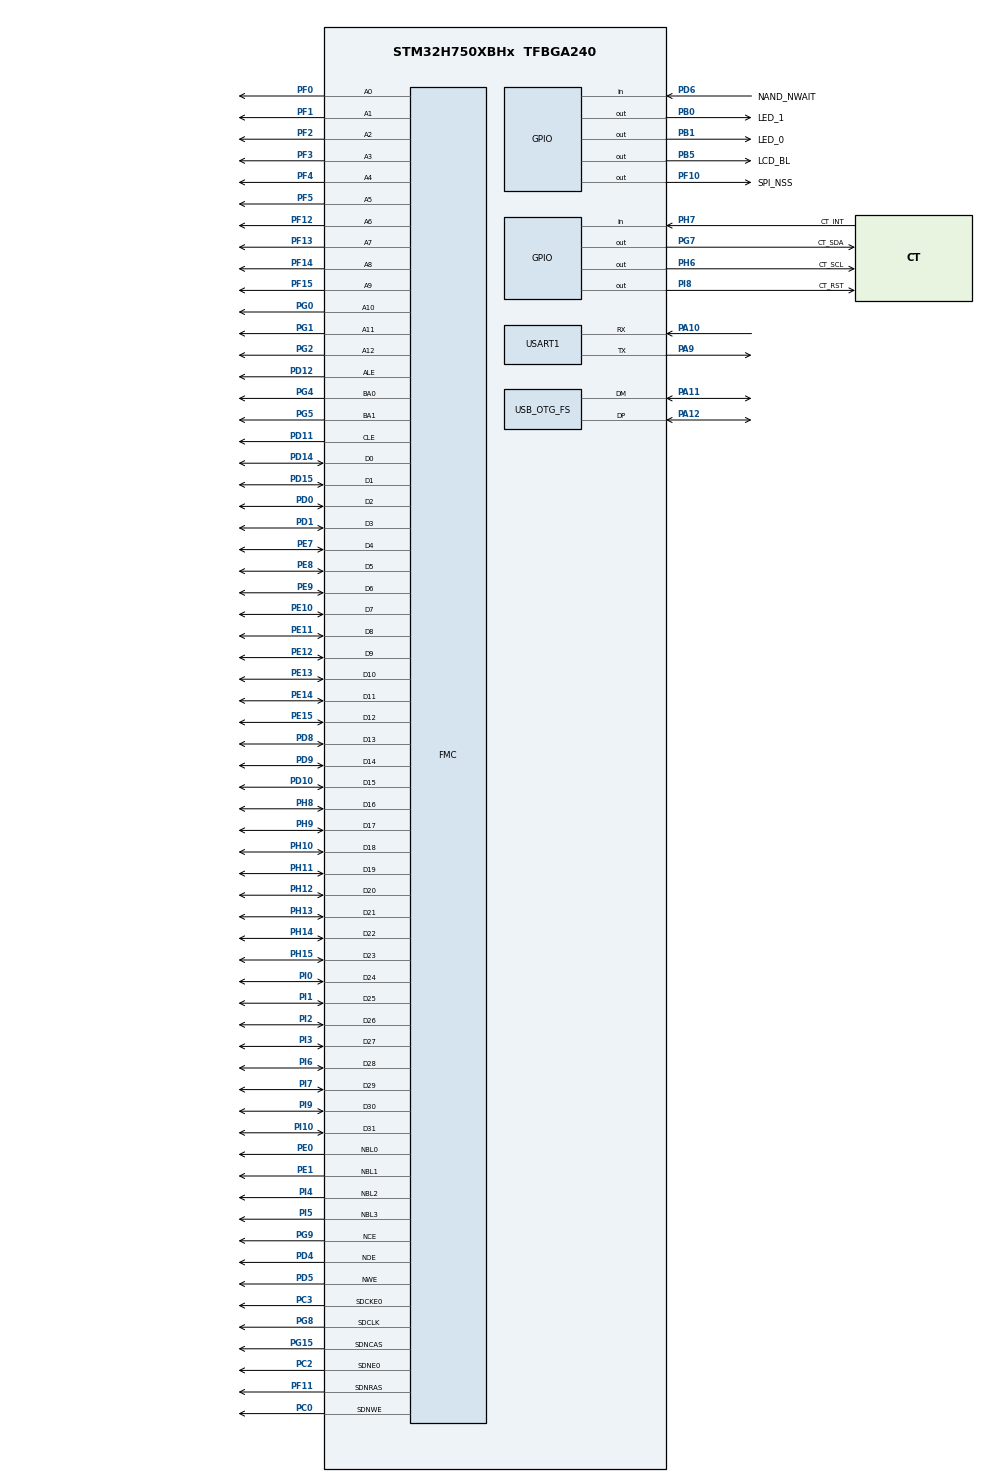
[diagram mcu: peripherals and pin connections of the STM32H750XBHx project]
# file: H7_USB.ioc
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CORTEX_M7.CPU_DCache=Enabled
CORTEX_M7.CPU_ICache=Enabled
CORTEX_M7.MPU_Control=__NULL
FMC.AttributeSpaceHiZSetupTime1=10
FMC.AttributeSpaceHoldSetupTime1=10
FMC.AttributeSpaceSetupTime1=10
FMC.AttributeSpaceWaitSetupTime1=10
FMC.CASLatency1=FMC_SDRAM_CAS_LATENCY_2
FMC.ColumnBitsNumber1=FMC_SDRAM_COLUMN_BITS_NUM_9
FMC.CommonSpaceHiZSetupTime1=10
FMC.CommonSpaceHoldSetupTime1=10
FMC.CommonSpaceSetupTime1=10
FMC.CommonSpaceWaitSetupTime1=10
FMC.ECCPageSize1=FMC_NAND_ECC_PAGE_SIZE_512BYTE
FMC.ExitSelfRefreshDelay1=8
FMC.LoadToActiveDelay1=2
FMC.NandBlockNbr1=2048
FMC.NandBlockSize1=64
FMC.NandPageSize1=2048
FMC.NandPlaneNbr1=2
FMC.NandPlaneSize1=4096
FMC.NandSpareAreaSize1=64
FMC.RCDDelay1=2
FMC.RPDelay1=2
FMC.RPDelay2=2
FMC.ReadBurst1=FMC_SDRAM_RBURST_ENABLE
FMC.ReadBurst2=FMC_SDRAM_RBURST_ENABLE
FMC.RowCycleDelay1=6
FMC.RowCycleDelay2=6
FMC.SDClockPeriod1=FMC_SDRAM_CLOCK_PERIOD_2
FMC.SDClockPeriod2=FMC_SDRAM_CLOCK_PERIOD_2
FMC.SelfRefreshTime1=6
FMC.TARSetupTime1=10
FMC.TCLRSetupTime1=10
FMC.WriteRecoveryTime1=4
Mcu.Family=STM32H7
Mcu.Name=STM32H750XBHx
Mcu.Package=TFBGA240
NVIC.FMC_IRQn=true\:0\:0\:false\:false\:true\:true\:true\:true
NVIC.OTG_FS_EP1_IN_IRQn=true\:0\:0\:false\:false\:true\:true\:true\:true
NVIC.OTG_FS_EP1_OUT_IRQn=true\:0\:0\:false\:false\:true\:true\:true\:true
NVIC.OTG_FS_IRQn=true\:1\:0\:true\:false\:true\:false\:true\:true
NVIC.PriorityGroup=NVIC_PRIORITYGROUP_4
PA10.Mode=Asynchronous
PA10.Signal=USART1_RX
PA11.GPIO_Speed=GPIO_SPEED_FREQ_MEDIUM
PA11.Mode=Device_Only
PA11.Signal=USB_OTG_FS_DM
PA12.GPIO_Speed=GPIO_SPEED_FREQ_MEDIUM
PA12.Mode=Device_Only
PA12.Signal=USB_OTG_FS_DP
PA13\ (JTMS/SWDIO).Mode=Serial_Wire
PA13\ (JTMS/SWDIO).Signal=DEBUG_JTMS-SWDIO
PA14\ (JTCK/SWCLK).Mode=Serial_Wire
PA14\ (JTCK/SWCLK).Signal=DEBUG_JTCK-SWCLK
PA9.Mode=Asynchronous
PA9.Signal=USART1_TX
PB0.GPIO_Label=LED_1
PB0.GPIO_PuPd=GPIO_PULLUP
PB0.PinState=GPIO_PIN_SET
PB0.Signal=GPIO_Output
PB1.GPIO_Label=LED_0
PB1.GPIO_PuPd=GPIO_PULLUP
PB1.PinState=GPIO_PIN_SET
PB1.Signal=GPIO_Output
PB13.GPIO_Speed=GPIO_SPEED_FREQ_HIGH
PB13.Signal=SPI2_SCK
PB14.GPIO_Speed=GPIO_SPEED_FREQ_HIGH
PB14.Signal=SPI2_MISO
PB15.GPIO_Speed=GPIO_SPEED_FREQ_HIGH
PB15.Signal=SPI2_MOSI
PB5.GPIO_Label=LCD_BL
PB5.GPIO_PuPd=GPIO_PULLUP
PB5.PinState=GPIO_PIN_SET
PB5.Signal=GPIO_Output
PC0.GPIO_PuPd=GPIO_PULLUP
PC0.Signal=FMC_SDNWE
PC2.GPIO_PuPd=GPIO_PULLUP
PC2.Mode=SdramChipSelect1_1
PC2.Signal=FMC_SDNE0
PC3.GPIO_PuPd=GPIO_PULLUP
PC3.Mode=SdramChipSelect1_1
PC3.Signal=FMC_SDCKE0
PD0.Signal=FMC_D2_DA2
PD1.Signal=FMC_D3_DA3
PD10.Signal=FMC_D15_DA15
PD11.Signal=FMC_A16_CLE
PD12.Signal=FMC_A17_ALE
PD14.Signal=FMC_D0_DA0
PD15.Signal=FMC_D1_DA1
PD4.Signal=FMC_NOE
PD5.Signal=FMC_NWE
PD6.GPIO_Label=NAND_NWAIT
PD6.GPIO_PuPd=GPIO_PULLUP
PD6.Signal=GPIO_Input
PD8.Signal=FMC_D13_DA13
PD9.Signal=FMC_D14_DA14
PE0.Signal=FMC_NBL0
PE1.Signal=FMC_NBL1
PE10.Signal=FMC_D7_DA7
PE11.Signal=FMC_D8_DA8
PE12.Signal=FMC_D9_DA9
PE13.Signal=FMC_D10_DA10
PE14.Signal=FMC_D11_DA11
PE15.Signal=FMC_D12_DA12
PE7.Signal=FMC_D4_DA4
PE8.Signal=FMC_D5_DA5
PE9.Signal=FMC_D6_DA6
PF0.Signal=FMC_A0
PF1.Signal=FMC_A1
PF10.GPIO_Label=SPI_NSS
PF10.GPIO_PuPd=GPIO_PULLUP
PF10.GPIO_Speed=GPIO_SPEED_FREQ_HIGH
PF10.Signal=GPIO_Output
PF11.Signal=FMC_SDNRAS
PF12.Signal=FMC_A6
PF13.Signal=FMC_A7
PF14.Signal=FMC_A8
PF15.Signal=FMC_A9
PF2.Signal=FMC_A2
PF3.Signal=FMC_A3
PF4.Signal=FMC_A4
PF5.Signal=FMC_A5
PG0.Signal=FMC_A10
PG1.Signal=FMC_A11
PG15.Signal=FMC_SDNCAS
PG2.Signal=FMC_A12
PG4.Signal=FMC_A14_BA0
PG5.Signal=FMC_A15_BA1
PG7.GPIO_Label=CT_SDA
PG7.GPIO_ModeDefaultOutputPP=GPIO_MODE_OUTPUT_OD
PG7.GPIO_PuPd=GPIO_PULLUP
PG7.Signal=GPIO_Output
PG8.Signal=FMC_SDCLK
PG9.Mode=NandChipSelect3_1
PG9.Signal=FMC_NCE
PH0-OSC_IN\ (PH0).Mode=HSE-External-Oscillator
PH0-OSC_IN\ (PH0).Signal=RCC_OSC_IN
PH1-OSC_OUT\ (PH1).Mode=HSE-External-Oscillator
PH1-OSC_OUT\ (PH1).Signal=RCC_OSC_OUT
PH10.Signal=FMC_D18
PH11.Signal=FMC_D19
PH12.Signal=FMC_D20
PH13.Signal=FMC_D21
PH14.Signal=FMC_D22
PH15.Signal=FMC_D23
PH6.GPIO_Label=CT_SCL
PH6.GPIO_ModeDefaultOutputPP=GPIO_MODE_OUTPUT_OD
PH6.GPIO_PuPd=GPIO_PULLUP
PH6.Signal=GPIO_Output
PH7.GPIO_Label=CT_INT
PH7.GPIO_PuPd=GPIO_PULLUP
PH7.Signal=GPIO_Input
PH8.Signal=FMC_D16
PH9.Signal=FMC_D17
PI0.Signal=FMC_D24
PI1.Signal=FMC_D25
PI10.Signal=FMC_D31
PI12.GPIO_Speed=GPIO_SPEED_FREQ_MEDIUM
PI12.Signal=LTDC_HSYNC
PI13.GPIO_Speed=GPIO_SPEED_FREQ_MEDIUM
PI13.Signal=LTDC_VSYNC
PI14.GPIO_Speed=GPIO_SPEED_FREQ_MEDIUM
PI14.Signal=LTDC_CLK
PI15.GPIO_Speed=GPIO_SPEED_FREQ_MEDIUM
PI15.Signal=LTDC_R0
PI2.Signal=FMC_D26
PI3.Signal=FMC_D27
PI4.Signal=FMC_NBL2
PI5.Signal=FMC_NBL3
PI6.Signal=FMC_D28
PI7.Signal=FMC_D29
PI8.GPIO_Label=CT_RST
PI8.GPIO_PuPd=GPIO_PULLUP
PI8.Signal=GPIO_Output
PI9.Signal=FMC_D30
PJ0.GPIO_Speed=GPIO_SPEED_FREQ_MEDIUM
PJ0.Signal=LTDC_R1
PJ1.GPIO_Speed=GPIO_SPEED_FREQ_MEDIUM
PJ1.Signal=LTDC_R2
PJ10.GPIO_Speed=GPIO_SPEED_FREQ_MEDIUM
PJ10.Signal=LTDC_G3
PJ11.GPIO_Speed=GPIO_SPEED_FREQ_MEDIUM
PJ11.Signal=LTDC_G4
PJ12.GPIO_Speed=GPIO_SPEED_FREQ_MEDIUM
PJ12.Signal=LTDC_B0
PJ13.GPIO_Speed=GPIO_SPEED_FREQ_MEDIUM
PJ13.Signal=LTDC_B1
PJ14.GPIO_Speed=GPIO_SPEED_FREQ_MEDIUM
PJ14.Signal=LTDC_B2
PJ15.GPIO_Speed=GPIO_SPEED_FREQ_MEDIUM
PJ15.Signal=LTDC_B3
PJ2.GPIO_Speed=GPIO_SPEED_FREQ_MEDIUM
PJ2.Signal=LTDC_R3
PJ3.GPIO_Speed=GPIO_SPEED_FREQ_MEDIUM
PJ3.Signal=LTDC_R4
PJ4.GPIO_Speed=GPIO_SPEED_FREQ_MEDIUM
PJ4.Signal=LTDC_R5
PJ5.GPIO_Speed=GPIO_SPEED_FREQ_MEDIUM
PJ5.Signal=LTDC_R6
PJ6.GPIO_Speed=GPIO_SPEED_FREQ_MEDIUM
PJ6.Signal=LTDC_R7
PJ7.GPIO_Speed=GPIO_SPEED_FREQ_MEDIUM
PJ7.Signal=LTDC_G0
PJ8.GPIO_Speed=GPIO_SPEED_FREQ_MEDIUM
PJ8.Signal=LTDC_G1
PJ9.GPIO_Speed=GPIO_SPEED_FREQ_MEDIUM
PJ9.Signal=LTDC_G2
PK0.GPIO_Speed=GPIO_SPEED_FREQ_MEDIUM
PK0.Signal=LTDC_G5
PK1.GPIO_Speed=GPIO_SPEED_FREQ_MEDIUM
PK1.Signal=LTDC_G6
PK2.GPIO_Speed=GPIO_SPEED_FREQ_MEDIUM
PK2.Signal=LTDC_G7
PK3.GPIO_Speed=GPIO_SPEED_FREQ_MEDIUM
PK3.Signal=LTDC_B4
PK4.GPIO_Speed=GPIO_SPEED_FREQ_MEDIUM
PK4.Signal=LTDC_B5
PK5.GPIO_Speed=GPIO_SPEED_FREQ_MEDIUM
PK5.Signal=LTDC_B6
PK6.GPIO_Speed=GPIO_SPEED_FREQ_MEDIUM
PK6.Signal=LTDC_B7
ProjectManager.HeapSize=0x2000
ProjectManager.StackSize=0x2000
ProjectManager.TargetToolchain=Makefile
RCC.ADCFreq_Value=75000000
RCC.APB1Freq_Value=100000000
RCC.APB2Freq_Value=100000000
RCC.APB3Freq_Value=100000000
RCC.APB4Freq_Value=100000000
RCC.CortexFreq_Value=400000000
RCC.D1PPRE=RCC_APB3_DIV2
RCC.D2PPRE1=RCC_APB1_DIV2
RCC.D2PPRE2=RCC_APB2_DIV2
RCC.D3PPRE=RCC_APB4_DIV2
RCC.DIVM1=2
RCC.DIVM2=10
RCC.DIVM3=5
RCC.DIVN1=64
RCC.DIVN2=60
RCC.DIVN3=32
RCC.DIVQ1=4
RCC.DIVQ2=5
RCC.DIVR3=5
RCC.HCLKFreq_Value=200000000
RCC.HPRE=RCC_HCLK_DIV2
RCC.PLL2FRACN=0
RCC.PLL3FRACN=0
RCC.PLLFRACN=0
RCC.PLLSourceVirtual=RCC_PLLSOURCE_HSE
RCC.PWR_Regulator_Voltage_Scale=PWR_REGULATOR_VOLTAGE_SCALE1
RCC.ProductRev=revV
RCC.SDMMC1CLockSelection=RCC_SDMMCCLKSOURCE_PLL2
RCC.SYSCLKFreq_VALUE=400000000
RCC.SYSCLKSource=RCC_SYSCLKSOURCE_PLLCLK
RCC.USART16CLockSelection=RCC_USART16CLKSOURCE_PLL2
RCC.USBCLockSelection=RCC_USBCLKSOURCE_HSI48
RCC.USBFreq_Value=48000000
SH.FMC_A0.0=FMC_A0,13b-sda1
SH.FMC_A1.0=FMC_A1,13b-sda1
SH.FMC_A10.0=FMC_A10,13b-sda1
SH.FMC_A11.0=FMC_A11,13b-sda1
SH.FMC_A12.0=FMC_A12,13b-sda1
SH.FMC_A14_BA0.0=FMC_BA0,FourSdramBanks1
SH.FMC_A15_BA1.0=FMC_BA1,FourSdramBanks1
SH.FMC_A16_CLE.0=FMC_CLE,8b-dmux1
SH.FMC_A17_ALE.0=FMC_ALE,8b-dmux1
SH.FMC_A2.0=FMC_A2,13b-sda1
SH.FMC_A3.0=FMC_A3,13b-sda1
SH.FMC_A4.0=FMC_A4,13b-sda1
SH.FMC_A5.0=FMC_A5,13b-sda1
SH.FMC_A6.0=FMC_A6,13b-sda1
SH.FMC_A7.0=FMC_A7,13b-sda1
SH.FMC_A8.0=FMC_A8,13b-sda1
SH.FMC_A9.0=FMC_A9,13b-sda1
SH.FMC_D0_DA0.0=FMC_D0,8b-dmux1
SH.FMC_D0_DA0.1=FMC_D0,sd-32b-d1
SH.FMC_D10_DA10.0=FMC_D10,sd-32b-d1
SH.FMC_D11_DA11.0=FMC_D11,sd-32b-d1
SH.FMC_D12_DA12.0=FMC_D12,sd-32b-d1
SH.FMC_D13_DA13.0=FMC_D13,sd-32b-d1
SH.FMC_D14_DA14.0=FMC_D14,sd-32b-d1
SH.FMC_D15_DA15.0=FMC_D15,sd-32b-d1
SH.FMC_D16.0=FMC_D16,sd-32b-d1
SH.FMC_D17.0=FMC_D17,sd-32b-d1
SH.FMC_D18.0=FMC_D18,sd-32b-d1
SH.FMC_D19.0=FMC_D19,sd-32b-d1
SH.FMC_D1_DA1.0=FMC_D1,8b-dmux1
SH.FMC_D1_DA1.1=FMC_D1,sd-32b-d1
SH.FMC_D20.0=FMC_D20,sd-32b-d1
SH.FMC_D21.0=FMC_D21,sd-32b-d1
SH.FMC_D22.0=FMC_D22,sd-32b-d1
SH.FMC_D23.0=FMC_D23,sd-32b-d1
SH.FMC_D24.0=FMC_D24,sd-32b-d1
SH.FMC_D25.0=FMC_D25,sd-32b-d1
SH.FMC_D26.0=FMC_D26,sd-32b-d1
SH.FMC_D27.0=FMC_D27,sd-32b-d1
SH.FMC_D28.0=FMC_D28,sd-32b-d1
SH.FMC_D29.0=FMC_D29,sd-32b-d1
SH.FMC_D2_DA2.0=FMC_D2,8b-dmux1
SH.FMC_D2_DA2.1=FMC_D2,sd-32b-d1
SH.FMC_D30.0=FMC_D30,sd-32b-d1
SH.FMC_D31.0=FMC_D31,sd-32b-d1
SH.FMC_D3_DA3.0=FMC_D3,8b-dmux1
SH.FMC_D3_DA3.1=FMC_D3,sd-32b-d1
SH.FMC_D4_DA4.0=FMC_D4,8b-dmux1
SH.FMC_D4_DA4.1=FMC_D4,sd-32b-d1
SH.FMC_D5_DA5.0=FMC_D5,8b-dmux1
SH.FMC_D5_DA5.1=FMC_D5,sd-32b-d1
SH.FMC_D6_DA6.0=FMC_D6,8b-dmux1
SH.FMC_D6_DA6.1=FMC_D6,sd-32b-d1
SH.FMC_D7_DA7.0=FMC_D7,8b-dmux1
SH.FMC_D7_DA7.1=FMC_D7,sd-32b-d1
SH.FMC_D8_DA8.0=FMC_D8,sd-32b-d1
SH.FMC_D9_DA9.0=FMC_D9,sd-32b-d1
SH.FMC_NBL0.0=FMC_NBL0,Sd4ByteEnable1
SH.FMC_NBL1.0=FMC_NBL1,Sd4ByteEnable1
SH.FMC_NBL2.0=FMC_NBL2,Sd4ByteEnable1
SH.FMC_NBL3.0=FMC_NBL3,Sd4ByteEnable1
SH.FMC_NOE.0=FMC_NOE,8b-dmux1
SH.FMC_NWE.0=FMC_NWE,8b-dmux1
SH.FMC_SDCLK.0=FMC_SDCLK,13b-sda1
SH.FMC_SDNCAS.0=FMC_SDNCAS,13b-sda1
SH.FMC_SDNRAS.0=FMC_SDNRAS,13b-sda1
SH.FMC_SDNWE.0=FMC_SDNWE,13b-sda1
TIM6.Prescaler=199
USART1.FIFOMode=FIFOMODE_ENABLE
USART1.VirtualMode-Asynchronous=VM_ASYNC
USB_DEVICE.CLASS_NAME_FS=MSC
USB_DEVICE.MSC_MEDIA_PACKET-MSC_FS=512
USB_DEVICE.USBD_MAX_NUM_CONFIGURATION-MSC_FS=1
USB_DEVICE.USBD_MAX_NUM_INTERFACES-MSC_FS=1
USB_DEVICE.USBD_MAX_STR_DESC_SIZ-MSC_FS=512
USB_DEVICE.USBD_SELF_POWERED-MSC_FS=0
USB_DEVICE.VirtualMode-MSC_FS=Msc
USB_DEVICE.VirtualModeFS=Msc_FS
USB_OTG_FS.Sof_enable=DISABLE
USB_OTG_FS.VirtualMode=Device_Only
USB_OTG_FS.lpm_enable=DISABLE
VP_TIM6_VS_ClockSourceINT.Mode=Enable_Timer
VP_USB_DEVICE_VS_USB_DEVICE_MSC_FS.Mode=MSC_FS
board=custom

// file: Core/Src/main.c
/* USER CODE BEGIN Header */
/**
 ******************************************************************************
 * @file           : main.c
 * @brief          : Main program body
 ******************************************************************************
 * @attention
 *
 * Copyright (c) 2022 STMicroelectronics.
 * All rights reserved.
 *
 * This software is licensed under terms that can be found in the LICENSE file
 * in the root directory of this software component.
 * If no LICENSE file comes with this software, it is provided AS-IS.
 *
 ******************************************************************************
 */
/* USER CODE END Header */
#include "main.h"
#include "tim.h"
#include "usart.h"
#include "usb_device.h"
#include "gpio.h"
#include "fmc.h"

/* USER CODE BEGIN Includes */
#include "sdram.h"
#include "nand.h"
#include "malloc.h"
#include "ftl.h"
#include "pcf8574.h"
#include "mpu.h"
/* USER CODE END Includes */

void SystemClock_Config(void);

int main(void)
{

  /* Enable I-Cache---------------------------------------------------------*/
  SCB_EnableICache();

  /* Enable D-Cache---------------------------------------------------------*/
  SCB_EnableDCache();

  /* MCU Configuration--------------------------------------------------------*/

  /* Reset of all peripherals, Initializes the Flash interface and the Systick. */
  HAL_Init();

  /* Configure the system clock */
  SystemClock_Config();

  /* Initialize all configured peripherals */
  MX_GPIO_Init();
  MX_TIM6_Init();
  MX_FMC_Init();
  MX_USART1_UART_Init();
  MX_USB_DEVICE_Init();
  /* USER CODE BEGIN 2 */
  MPU_Memory_Protection();
  // PCF8574_Init();
  // PCF8574_WriteBit(USB_PWR_IO, 1);

  my_mem_init(SRAMIN);
  my_mem_init(SRAMEX);

  // FTL_Init();
  // FTL_Format();
  /* USER CODE END 2 */

  /* Infinite loop */
  /* USER CODE BEGIN WHILE */
  while (1)
  {
    HAL_GPIO_TogglePin(LED_0_GPIO_Port, LED_0_Pin);
    delay_ms(100);
    /* USER CODE END WHILE */

  }
}

void SystemClock_Config(void)
{
  RCC_OscInitTypeDef RCC_OscInitStruct = {0};
  RCC_ClkInitTypeDef RCC_ClkInitStruct = {0};

  /** Supply configuration update enable
  */
  HAL_PWREx_ConfigSupply(PWR_LDO_SUPPLY);

  /** Configure the main internal regulator output voltage
  */
  __HAL_PWR_VOLTAGESCALING_CONFIG(PWR_REGULATOR_VOLTAGE_SCALE1);

  while(!__HAL_PWR_GET_FLAG(PWR_FLAG_VOSRDY)) {}

  /** Macro to configure the PLL clock source
  */
  __HAL_RCC_PLL_PLLSOURCE_CONFIG(RCC_PLLSOURCE_HSE);

  /** Initializes the RCC Oscillators according to the specified parameters
  * in the RCC_OscInitTypeDef structure.
  */
  RCC_OscInitStruct.OscillatorType = RCC_OSCILLATORTYPE_HSI48|RCC_OSCILLATORTYPE_HSE;
  RCC_OscInitStruct.HSEState = RCC_HSE_ON;
  RCC_OscInitStruct.HSI48State = RCC_HSI48_ON;
  RCC_OscInitStruct.PLL.PLLState = RCC_PLL_ON;
  RCC_OscInitStruct.PLL.PLLSource = RCC_PLLSOURCE_HSE;
  RCC_OscInitStruct.PLL.PLLM = 2;
  RCC_OscInitStruct.PLL.PLLN = 64;
  RCC_OscInitStruct.PLL.PLLP = 2;
  RCC_OscInitStruct.PLL.PLLQ = 4;
  RCC_OscInitStruct.PLL.PLLR = 2;
  RCC_OscInitStruct.PLL.PLLRGE = RCC_PLL1VCIRANGE_3;
  RCC_OscInitStruct.PLL.PLLVCOSEL = RCC_PLL1VCOWIDE;
  RCC_OscInitStruct.PLL.PLLFRACN = 0;
  if (HAL_RCC_OscConfig(&RCC_OscInitStruct) != HAL_OK)
  {
    Error_Handler();
  }

  /** Initializes the CPU, AHB and APB buses clocks
  */
  RCC_ClkInitStruct.ClockType = RCC_CLOCKTYPE_HCLK|RCC_CLOCKTYPE_SYSCLK
                              |RCC_CLOCKTYPE_PCLK1|RCC_CLOCKTYPE_PCLK2
                              |RCC_CLOCKTYPE_D3PCLK1|RCC_CLOCKTYPE_D1PCLK1;
  RCC_ClkInitStruct.SYSCLKSource = RCC_SYSCLKSOURCE_PLLCLK;
  RCC_ClkInitStruct.SYSCLKDivider = RCC_SYSCLK_DIV1;
  RCC_ClkInitStruct.AHBCLKDivider = RCC_HCLK_DIV2;
  RCC_ClkInitStruct.APB3CLKDivider = RCC_APB3_DIV2;
  RCC_ClkInitStruct.APB1CLKDivider = RCC_APB1_DIV2;
  RCC_ClkInitStruct.APB2CLKDivider = RCC_APB2_DIV2;
  RCC_ClkInitStruct.APB4CLKDivider = RCC_APB4_DIV2;

  if (HAL_RCC_ClockConfig(&RCC_ClkInitStruct, FLASH_LATENCY_2) != HAL_OK)
  {
    Error_Handler();
  }
}

void Error_Handler(void)
{
  __disable_irq();
  while (1)
  {
  }
}
